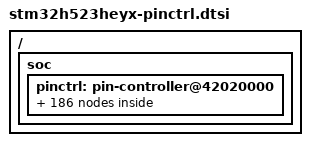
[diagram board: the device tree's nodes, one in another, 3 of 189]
/*
 * NOTE: Autogenerated file using genpinctrl.py
 *
 * SPDX-License-Identifier: Apache-2.0
 */

#include <zephyr/dt-bindings/pinctrl/stm32-pinctrl.h>

/ {
	soc {
		pinctrl: pin-controller@42020000 {

			/* ADC_IN / ADC_INN / ADC_INP */

			/omit-if-no-ref/ adc1_inn1_pa0: adc1_inn1_pa0 {
				pinmux = <STM32_PINMUX('A', 0, ANALOG)>;
			};

			/omit-if-no-ref/ adc1_inp0_pa0: adc1_inp0_pa0 {
				pinmux = <STM32_PINMUX('A', 0, ANALOG)>;
			};

			/omit-if-no-ref/ adc1_inp1_pa1: adc1_inp1_pa1 {
				pinmux = <STM32_PINMUX('A', 1, ANALOG)>;
			};

			/omit-if-no-ref/ adc1_inp14_pa2: adc1_inp14_pa2 {
				pinmux = <STM32_PINMUX('A', 2, ANALOG)>;
			};

			/omit-if-no-ref/ adc1_inp15_pa3: adc1_inp15_pa3 {
				pinmux = <STM32_PINMUX('A', 3, ANALOG)>;
			};

			/omit-if-no-ref/ adc1_inp18_pa4: adc1_inp18_pa4 {
				pinmux = <STM32_PINMUX('A', 4, ANALOG)>;
			};

			/omit-if-no-ref/ adc1_inn18_pa5: adc1_inn18_pa5 {
				pinmux = <STM32_PINMUX('A', 5, ANALOG)>;
			};

			/omit-if-no-ref/ adc1_inp19_pa5: adc1_inp19_pa5 {
				pinmux = <STM32_PINMUX('A', 5, ANALOG)>;
			};

			/omit-if-no-ref/ adc1_inp3_pa6: adc1_inp3_pa6 {
				pinmux = <STM32_PINMUX('A', 6, ANALOG)>;
			};

			/omit-if-no-ref/ adc1_inn3_pa7: adc1_inn3_pa7 {
				pinmux = <STM32_PINMUX('A', 7, ANALOG)>;
			};

			/omit-if-no-ref/ adc1_inp7_pa7: adc1_inp7_pa7 {
				pinmux = <STM32_PINMUX('A', 7, ANALOG)>;
			};

			/omit-if-no-ref/ adc1_inn5_pb0: adc1_inn5_pb0 {
				pinmux = <STM32_PINMUX('B', 0, ANALOG)>;
			};

			/omit-if-no-ref/ adc1_inp9_pb0: adc1_inp9_pb0 {
				pinmux = <STM32_PINMUX('B', 0, ANALOG)>;
			};

			/omit-if-no-ref/ adc1_inp5_pb1: adc1_inp5_pb1 {
				pinmux = <STM32_PINMUX('B', 1, ANALOG)>;
			};

			/omit-if-no-ref/ adc2_inn1_pa0: adc2_inn1_pa0 {
				pinmux = <STM32_PINMUX('A', 0, ANALOG)>;
			};

			/omit-if-no-ref/ adc2_inp0_pa0: adc2_inp0_pa0 {
				pinmux = <STM32_PINMUX('A', 0, ANALOG)>;
			};

			/omit-if-no-ref/ adc2_inp1_pa1: adc2_inp1_pa1 {
				pinmux = <STM32_PINMUX('A', 1, ANALOG)>;
			};

			/omit-if-no-ref/ adc2_inp14_pa2: adc2_inp14_pa2 {
				pinmux = <STM32_PINMUX('A', 2, ANALOG)>;
			};

			/omit-if-no-ref/ adc2_inp15_pa3: adc2_inp15_pa3 {
				pinmux = <STM32_PINMUX('A', 3, ANALOG)>;
			};

			/omit-if-no-ref/ adc2_inp18_pa4: adc2_inp18_pa4 {
				pinmux = <STM32_PINMUX('A', 4, ANALOG)>;
			};

			/omit-if-no-ref/ adc2_inn18_pa5: adc2_inn18_pa5 {
				pinmux = <STM32_PINMUX('A', 5, ANALOG)>;
			};

			/omit-if-no-ref/ adc2_inp19_pa5: adc2_inp19_pa5 {
				pinmux = <STM32_PINMUX('A', 5, ANALOG)>;
			};

			/omit-if-no-ref/ adc2_inp3_pa6: adc2_inp3_pa6 {
				pinmux = <STM32_PINMUX('A', 6, ANALOG)>;
			};

			/omit-if-no-ref/ adc2_inn3_pa7: adc2_inn3_pa7 {
				pinmux = <STM32_PINMUX('A', 7, ANALOG)>;
			};

			/omit-if-no-ref/ adc2_inp7_pa7: adc2_inp7_pa7 {
				pinmux = <STM32_PINMUX('A', 7, ANALOG)>;
			};

			/omit-if-no-ref/ adc2_inn5_pb0: adc2_inn5_pb0 {
				pinmux = <STM32_PINMUX('B', 0, ANALOG)>;
			};

			/omit-if-no-ref/ adc2_inp9_pb0: adc2_inp9_pb0 {
				pinmux = <STM32_PINMUX('B', 0, ANALOG)>;
			};

			/omit-if-no-ref/ adc2_inp5_pb1: adc2_inp5_pb1 {
				pinmux = <STM32_PINMUX('B', 1, ANALOG)>;
			};

			/* Analog */

			/omit-if-no-ref/ analog_pa0: analog_pa0 {
				pinmux = <STM32_PINMUX('A', 0, ANALOG)>;
			};

			/omit-if-no-ref/ analog_pa1: analog_pa1 {
				pinmux = <STM32_PINMUX('A', 1, ANALOG)>;
			};

			/omit-if-no-ref/ analog_pa2: analog_pa2 {
				pinmux = <STM32_PINMUX('A', 2, ANALOG)>;
			};

			/omit-if-no-ref/ analog_pa3: analog_pa3 {
				pinmux = <STM32_PINMUX('A', 3, ANALOG)>;
			};

			/omit-if-no-ref/ analog_pa4: analog_pa4 {
				pinmux = <STM32_PINMUX('A', 4, ANALOG)>;
			};

			/omit-if-no-ref/ analog_pa5: analog_pa5 {
				pinmux = <STM32_PINMUX('A', 5, ANALOG)>;
			};

			/omit-if-no-ref/ analog_pa6: analog_pa6 {
				pinmux = <STM32_PINMUX('A', 6, ANALOG)>;
			};

			/omit-if-no-ref/ analog_pa7: analog_pa7 {
				pinmux = <STM32_PINMUX('A', 7, ANALOG)>;
			};

			/omit-if-no-ref/ analog_pa8: analog_pa8 {
				pinmux = <STM32_PINMUX('A', 8, ANALOG)>;
			};

			/omit-if-no-ref/ analog_pa11: analog_pa11 {
				pinmux = <STM32_PINMUX('A', 11, ANALOG)>;
			};

			/omit-if-no-ref/ analog_pa12: analog_pa12 {
				pinmux = <STM32_PINMUX('A', 12, ANALOG)>;
			};

			/omit-if-no-ref/ analog_pa13: analog_pa13 {
				pinmux = <STM32_PINMUX('A', 13, ANALOG)>;
			};

			/omit-if-no-ref/ analog_pa14: analog_pa14 {
				pinmux = <STM32_PINMUX('A', 14, ANALOG)>;
			};

			/omit-if-no-ref/ analog_pa15: analog_pa15 {
				pinmux = <STM32_PINMUX('A', 15, ANALOG)>;
			};

			/omit-if-no-ref/ analog_pb0: analog_pb0 {
				pinmux = <STM32_PINMUX('B', 0, ANALOG)>;
			};

			/omit-if-no-ref/ analog_pb1: analog_pb1 {
				pinmux = <STM32_PINMUX('B', 1, ANALOG)>;
			};

			/omit-if-no-ref/ analog_pb3: analog_pb3 {
				pinmux = <STM32_PINMUX('B', 3, ANALOG)>;
			};

			/omit-if-no-ref/ analog_pb4: analog_pb4 {
				pinmux = <STM32_PINMUX('B', 4, ANALOG)>;
			};

			/omit-if-no-ref/ analog_pb7: analog_pb7 {
				pinmux = <STM32_PINMUX('B', 7, ANALOG)>;
			};

			/omit-if-no-ref/ analog_pb8: analog_pb8 {
				pinmux = <STM32_PINMUX('B', 8, ANALOG)>;
			};

			/omit-if-no-ref/ analog_pb15: analog_pb15 {
				pinmux = <STM32_PINMUX('B', 15, ANALOG)>;
			};

			/omit-if-no-ref/ analog_pc13: analog_pc13 {
				pinmux = <STM32_PINMUX('C', 13, ANALOG)>;
			};

			/omit-if-no-ref/ analog_pc14: analog_pc14 {
				pinmux = <STM32_PINMUX('C', 14, ANALOG)>;
			};

			/omit-if-no-ref/ analog_pc15: analog_pc15 {
				pinmux = <STM32_PINMUX('C', 15, ANALOG)>;
			};

			/omit-if-no-ref/ analog_ph0: analog_ph0 {
				pinmux = <STM32_PINMUX('H', 0, ANALOG)>;
			};

			/omit-if-no-ref/ analog_ph1: analog_ph1 {
				pinmux = <STM32_PINMUX('H', 1, ANALOG)>;
			};

			/* DAC_OUT */

			/omit-if-no-ref/ dac1_out1_pa4: dac1_out1_pa4 {
				pinmux = <STM32_PINMUX('A', 4, ANALOG)>;
			};

			/omit-if-no-ref/ dac1_out2_pa5: dac1_out2_pa5 {
				pinmux = <STM32_PINMUX('A', 5, ANALOG)>;
			};

			/* FDCAN_RX */

			/omit-if-no-ref/ fdcan1_rx_pa11: fdcan1_rx_pa11 {
				pinmux = <STM32_PINMUX('A', 11, AF9)>;
			};

			/omit-if-no-ref/ fdcan1_rx_pb8: fdcan1_rx_pb8 {
				pinmux = <STM32_PINMUX('B', 8, AF9)>;
			};

			/omit-if-no-ref/ fdcan2_rx_pa0: fdcan2_rx_pa0 {
				pinmux = <STM32_PINMUX('A', 0, AF9)>;
			};

			/* FDCAN_TX */

			/omit-if-no-ref/ fdcan1_tx_pa12: fdcan1_tx_pa12 {
				pinmux = <STM32_PINMUX('A', 12, AF9)>;
			};

			/omit-if-no-ref/ fdcan1_tx_pb7: fdcan1_tx_pb7 {
				pinmux = <STM32_PINMUX('B', 7, AF9)>;
			};

			/omit-if-no-ref/ fdcan2_tx_pb3: fdcan2_tx_pb3 {
				pinmux = <STM32_PINMUX('B', 3, AF9)>;
			};

			/* I2C_SCL */

			/omit-if-no-ref/ i2c1_scl_pb8: i2c1_scl_pb8 {
				pinmux = <STM32_PINMUX('B', 8, AF4)>;
				bias-pull-up;
				drive-open-drain;
			};

			/* I2C_SDA */

			/omit-if-no-ref/ i2c1_sda_pb7: i2c1_sda_pb7 {
				pinmux = <STM32_PINMUX('B', 7, AF4)>;
				bias-pull-up;
				drive-open-drain;
			};

			/omit-if-no-ref/ i2c2_sda_pb3: i2c2_sda_pb3 {
				pinmux = <STM32_PINMUX('B', 3, AF4)>;
				bias-pull-up;
				drive-open-drain;
			};

			/* I2S_CK */

			/omit-if-no-ref/ i2s1_ck_pa5: i2s1_ck_pa5 {
				pinmux = <STM32_PINMUX('A', 5, AF5)>;
				slew-rate = "very-high-speed";
			};

			/omit-if-no-ref/ i2s1_ck_pb3: i2s1_ck_pb3 {
				pinmux = <STM32_PINMUX('B', 3, AF5)>;
				slew-rate = "very-high-speed";
			};

			/omit-if-no-ref/ i2s2_ck_pa12: i2s2_ck_pa12 {
				pinmux = <STM32_PINMUX('A', 12, AF5)>;
				slew-rate = "very-high-speed";
			};

			/* I2S_WS */

			/omit-if-no-ref/ i2s1_ws_pa4: i2s1_ws_pa4 {
				pinmux = <STM32_PINMUX('A', 4, AF5)>;
			};

			/omit-if-no-ref/ i2s1_ws_pa15: i2s1_ws_pa15 {
				pinmux = <STM32_PINMUX('A', 15, AF5)>;
			};

			/omit-if-no-ref/ i2s2_ws_pa3: i2s2_ws_pa3 {
				pinmux = <STM32_PINMUX('A', 3, AF5)>;
			};

			/omit-if-no-ref/ i2s2_ws_pa11: i2s2_ws_pa11 {
				pinmux = <STM32_PINMUX('A', 11, AF5)>;
			};

			/omit-if-no-ref/ i2s2_ws_pb1: i2s2_ws_pb1 {
				pinmux = <STM32_PINMUX('B', 1, AF5)>;
			};

			/omit-if-no-ref/ i2s2_ws_pb4: i2s2_ws_pb4 {
				pinmux = <STM32_PINMUX('B', 4, AF7)>;
			};

			/* I3C_SCL */

			/omit-if-no-ref/ i3c1_scl_pb8: i3c1_scl_pb8 {
				pinmux = <STM32_PINMUX('B', 8, AF3)>;
				slew-rate = "very-high-speed";
			};

			/omit-if-no-ref/ i3c2_scl_pa8: i3c2_scl_pa8 {
				pinmux = <STM32_PINMUX('A', 8, AF9)>;
				slew-rate = "very-high-speed";
			};

			/omit-if-no-ref/ i3c2_scl_pb3: i3c2_scl_pb3 {
				pinmux = <STM32_PINMUX('B', 3, AF3)>;
				slew-rate = "very-high-speed";
			};

			/* I3C_SDA */

			/omit-if-no-ref/ i3c1_sda_pb7: i3c1_sda_pb7 {
				pinmux = <STM32_PINMUX('B', 7, AF3)>;
				slew-rate = "very-high-speed";
			};

			/omit-if-no-ref/ i3c2_sda_pb4: i3c2_sda_pb4 {
				pinmux = <STM32_PINMUX('B', 4, AF10)>;
				slew-rate = "very-high-speed";
			};

			/* JTAG PORT */

			/omit-if-no-ref/ debug_jtms_swdio_pa13: debug_jtms_swdio_pa13 {
				pinmux = <STM32_PINMUX('A', 13, AF0)>;
			};

			/omit-if-no-ref/ debug_jtck_swclk_pa14: debug_jtck_swclk_pa14 {
				pinmux = <STM32_PINMUX('A', 14, AF0)>;
			};

			/omit-if-no-ref/ debug_jtdi_pa15: debug_jtdi_pa15 {
				pinmux = <STM32_PINMUX('A', 15, AF0)>;
			};

			/omit-if-no-ref/ debug_jtdo_swo_pb3: debug_jtdo_swo_pb3 {
				pinmux = <STM32_PINMUX('B', 3, AF0)>;
			};

			/omit-if-no-ref/ debug_njtrst_pb4: debug_njtrst_pb4 {
				pinmux = <STM32_PINMUX('B', 4, AF0)>;
			};

			/* OCTOSPI */

			/omit-if-no-ref/ octospi1_dqs_pa1: octospi1_dqs_pa1 {
				pinmux = <STM32_PINMUX('A', 1, AF6)>;
				slew-rate = "very-high-speed";
			};

			/omit-if-no-ref/ octospi1_io3_pa1: octospi1_io3_pa1 {
				pinmux = <STM32_PINMUX('A', 1, AF9)>;
				slew-rate = "very-high-speed";
			};

			/omit-if-no-ref/ octospi1_clk_pa3: octospi1_clk_pa3 {
				pinmux = <STM32_PINMUX('A', 3, AF3)>;
				slew-rate = "very-high-speed";
			};

			/omit-if-no-ref/ octospi1_io3_pa6: octospi1_io3_pa6 {
				pinmux = <STM32_PINMUX('A', 6, AF6)>;
				slew-rate = "very-high-speed";
			};

			/omit-if-no-ref/ octospi1_io2_pa7: octospi1_io2_pa7 {
				pinmux = <STM32_PINMUX('A', 7, AF10)>;
				slew-rate = "very-high-speed";
			};

			/omit-if-no-ref/ octospi1_ncs_pa15: octospi1_ncs_pa15 {
				pinmux = <STM32_PINMUX('A', 15, AF9)>;
				slew-rate = "very-high-speed";
			};

			/omit-if-no-ref/ octospi1_io1_pb0: octospi1_io1_pb0 {
				pinmux = <STM32_PINMUX('B', 0, AF6)>;
				slew-rate = "very-high-speed";
			};

			/omit-if-no-ref/ octospi1_io0_pb1: octospi1_io0_pb1 {
				pinmux = <STM32_PINMUX('B', 1, AF6)>;
				slew-rate = "very-high-speed";
			};

			/omit-if-no-ref/ octospi1_clk_pb4: octospi1_clk_pb4 {
				pinmux = <STM32_PINMUX('B', 4, AF3)>;
				slew-rate = "very-high-speed";
			};

			/omit-if-no-ref/ octospi1_clk_pb15: octospi1_clk_pb15 {
				pinmux = <STM32_PINMUX('B', 15, AF10)>;
				slew-rate = "very-high-speed";
			};

			/* RCC_MCO */

			/omit-if-no-ref/ rcc_mco_1_pa8: rcc_mco_1_pa8 {
				pinmux = <STM32_PINMUX('A', 8, AF0)>;
				slew-rate = "very-high-speed";
			};

			/* SPI_MISO */

			/omit-if-no-ref/ spi1_miso_pa6: spi1_miso_pa6 {
				pinmux = <STM32_PINMUX('A', 6, AF5)>;
				bias-pull-down;
			};

			/omit-if-no-ref/ spi1_miso_pb4: spi1_miso_pb4 {
				pinmux = <STM32_PINMUX('B', 4, AF5)>;
				bias-pull-down;
			};

			/omit-if-no-ref/ spi3_miso_pb0: spi3_miso_pb0 {
				pinmux = <STM32_PINMUX('B', 0, AF5)>;
				bias-pull-down;
			};

			/omit-if-no-ref/ spi3_miso_pb4: spi3_miso_pb4 {
				pinmux = <STM32_PINMUX('B', 4, AF6)>;
				bias-pull-down;
			};

			/* SPI_MOSI */

			/omit-if-no-ref/ spi1_mosi_pa7: spi1_mosi_pa7 {
				pinmux = <STM32_PINMUX('A', 7, AF5)>;
				bias-pull-down;
			};

			/omit-if-no-ref/ spi1_mosi_pb15: spi1_mosi_pb15 {
				pinmux = <STM32_PINMUX('B', 15, AF6)>;
				bias-pull-down;
			};

			/omit-if-no-ref/ spi2_mosi_pb15: spi2_mosi_pb15 {
				pinmux = <STM32_PINMUX('B', 15, AF5)>;
				bias-pull-down;
			};

			/omit-if-no-ref/ spi3_mosi_pa3: spi3_mosi_pa3 {
				pinmux = <STM32_PINMUX('A', 3, AF6)>;
				bias-pull-down;
			};

			/omit-if-no-ref/ spi3_mosi_pa4: spi3_mosi_pa4 {
				pinmux = <STM32_PINMUX('A', 4, AF4)>;
				bias-pull-down;
			};

			/* SPI_NSS */

			/omit-if-no-ref/ spi1_nss_pa4: spi1_nss_pa4 {
				pinmux = <STM32_PINMUX('A', 4, AF5)>;
				bias-pull-up;
			};

			/omit-if-no-ref/ spi1_nss_pa15: spi1_nss_pa15 {
				pinmux = <STM32_PINMUX('A', 15, AF5)>;
				bias-pull-up;
			};

			/omit-if-no-ref/ spi2_nss_pa3: spi2_nss_pa3 {
				pinmux = <STM32_PINMUX('A', 3, AF5)>;
				bias-pull-up;
			};

			/omit-if-no-ref/ spi2_nss_pa11: spi2_nss_pa11 {
				pinmux = <STM32_PINMUX('A', 11, AF5)>;
				bias-pull-up;
			};

			/omit-if-no-ref/ spi2_nss_pb1: spi2_nss_pb1 {
				pinmux = <STM32_PINMUX('B', 1, AF5)>;
				bias-pull-up;
			};

			/omit-if-no-ref/ spi2_nss_pb4: spi2_nss_pb4 {
				pinmux = <STM32_PINMUX('B', 4, AF7)>;
				bias-pull-up;
			};

			/omit-if-no-ref/ spi3_nss_pa4: spi3_nss_pa4 {
				pinmux = <STM32_PINMUX('A', 4, AF6)>;
				bias-pull-up;
			};

			/omit-if-no-ref/ spi3_nss_pa15: spi3_nss_pa15 {
				pinmux = <STM32_PINMUX('A', 15, AF6)>;
				bias-pull-up;
			};

			/omit-if-no-ref/ spi3_nss_pb8: spi3_nss_pb8 {
				pinmux = <STM32_PINMUX('B', 8, AF6)>;
				bias-pull-up;
			};

			/* SPI_SCK */

			/omit-if-no-ref/ spi1_sck_pa5: spi1_sck_pa5 {
				pinmux = <STM32_PINMUX('A', 5, AF5)>;
				bias-pull-down;
				slew-rate = "very-high-speed";
			};

			/omit-if-no-ref/ spi1_sck_pb3: spi1_sck_pb3 {
				pinmux = <STM32_PINMUX('B', 3, AF5)>;
				bias-pull-down;
				slew-rate = "very-high-speed";
			};

			/omit-if-no-ref/ spi2_sck_pa12: spi2_sck_pa12 {
				pinmux = <STM32_PINMUX('A', 12, AF5)>;
				bias-pull-down;
				slew-rate = "very-high-speed";
			};

			/omit-if-no-ref/ spi3_sck_pb1: spi3_sck_pb1 {
				pinmux = <STM32_PINMUX('B', 1, AF4)>;
				bias-pull-down;
				slew-rate = "very-high-speed";
			};

			/omit-if-no-ref/ spi3_sck_pb3: spi3_sck_pb3 {
				pinmux = <STM32_PINMUX('B', 3, AF6)>;
				bias-pull-down;
				slew-rate = "very-high-speed";
			};

			/* TIM_BKIN */

			/omit-if-no-ref/ tim1_bkin_pa6: tim1_bkin_pa6 {
				pinmux = <STM32_PINMUX('A', 6, AF1)>;
			};

			/omit-if-no-ref/ tim15_bkin_pa0: tim15_bkin_pa0 {
				pinmux = <STM32_PINMUX('A', 0, AF4)>;
			};

			/omit-if-no-ref/ tim8_bkin_pa6: tim8_bkin_pa6 {
				pinmux = <STM32_PINMUX('A', 6, AF3)>;
			};

			/omit-if-no-ref/ tim8_bkin2_pa8: tim8_bkin2_pa8 {
				pinmux = <STM32_PINMUX('A', 8, AF3)>;
			};

			/* TIM_CH / TIM_CHN */

			/omit-if-no-ref/ tim1_ch1n_pa7: tim1_ch1n_pa7 {
				pinmux = <STM32_PINMUX('A', 7, AF1)>;
			};

			/omit-if-no-ref/ tim1_ch1_pa8: tim1_ch1_pa8 {
				pinmux = <STM32_PINMUX('A', 8, AF1)>;
			};

			/omit-if-no-ref/ tim1_ch4_pa11: tim1_ch4_pa11 {
				pinmux = <STM32_PINMUX('A', 11, AF1)>;
			};

			/omit-if-no-ref/ tim1_ch2n_pb0: tim1_ch2n_pb0 {
				pinmux = <STM32_PINMUX('B', 0, AF1)>;
			};

			/omit-if-no-ref/ tim1_ch3n_pb1: tim1_ch3n_pb1 {
				pinmux = <STM32_PINMUX('B', 1, AF1)>;
			};

			/omit-if-no-ref/ tim1_ch3n_pb15: tim1_ch3n_pb15 {
				pinmux = <STM32_PINMUX('B', 15, AF1)>;
			};

			/omit-if-no-ref/ tim2_ch1_pa0: tim2_ch1_pa0 {
				pinmux = <STM32_PINMUX('A', 0, AF1)>;
			};

			/omit-if-no-ref/ tim2_ch2_pa1: tim2_ch2_pa1 {
				pinmux = <STM32_PINMUX('A', 1, AF1)>;
			};

			/omit-if-no-ref/ tim2_ch3_pa2: tim2_ch3_pa2 {
				pinmux = <STM32_PINMUX('A', 2, AF1)>;
			};

			/omit-if-no-ref/ tim2_ch4_pa3: tim2_ch4_pa3 {
				pinmux = <STM32_PINMUX('A', 3, AF1)>;
			};

			/omit-if-no-ref/ tim2_ch1_pa5: tim2_ch1_pa5 {
				pinmux = <STM32_PINMUX('A', 5, AF1)>;
			};

			/omit-if-no-ref/ tim2_ch1_pa15: tim2_ch1_pa15 {
				pinmux = <STM32_PINMUX('A', 15, AF1)>;
			};

			/omit-if-no-ref/ tim2_ch2_pb3: tim2_ch2_pb3 {
				pinmux = <STM32_PINMUX('B', 3, AF1)>;
			};

			/omit-if-no-ref/ tim12_ch2_pb15: tim12_ch2_pb15 {
				pinmux = <STM32_PINMUX('B', 15, AF2)>;
			};

			/omit-if-no-ref/ tim3_ch1_pa6: tim3_ch1_pa6 {
				pinmux = <STM32_PINMUX('A', 6, AF2)>;
			};

			/omit-if-no-ref/ tim3_ch2_pa7: tim3_ch2_pa7 {
				pinmux = <STM32_PINMUX('A', 7, AF2)>;
			};

			/omit-if-no-ref/ tim3_ch3_pb0: tim3_ch3_pb0 {
				pinmux = <STM32_PINMUX('B', 0, AF2)>;
			};

			/omit-if-no-ref/ tim3_ch4_pb1: tim3_ch4_pb1 {
				pinmux = <STM32_PINMUX('B', 1, AF2)>;
			};

			/omit-if-no-ref/ tim3_ch1_pb4: tim3_ch1_pb4 {
				pinmux = <STM32_PINMUX('B', 4, AF2)>;
			};

			/omit-if-no-ref/ tim4_ch2_pb7: tim4_ch2_pb7 {
				pinmux = <STM32_PINMUX('B', 7, AF2)>;
			};

			/omit-if-no-ref/ tim4_ch3_pb8: tim4_ch3_pb8 {
				pinmux = <STM32_PINMUX('B', 8, AF2)>;
			};

			/omit-if-no-ref/ tim5_ch1_pa0: tim5_ch1_pa0 {
				pinmux = <STM32_PINMUX('A', 0, AF2)>;
			};

			/omit-if-no-ref/ tim15_ch1n_pa1: tim15_ch1n_pa1 {
				pinmux = <STM32_PINMUX('A', 1, AF4)>;
			};

			/omit-if-no-ref/ tim5_ch2_pa1: tim5_ch2_pa1 {
				pinmux = <STM32_PINMUX('A', 1, AF2)>;
			};

			/omit-if-no-ref/ tim15_ch1_pa2: tim15_ch1_pa2 {
				pinmux = <STM32_PINMUX('A', 2, AF4)>;
			};

			/omit-if-no-ref/ tim5_ch3_pa2: tim5_ch3_pa2 {
				pinmux = <STM32_PINMUX('A', 2, AF2)>;
			};

			/omit-if-no-ref/ tim15_ch2_pa3: tim15_ch2_pa3 {
				pinmux = <STM32_PINMUX('A', 3, AF4)>;
			};

			/omit-if-no-ref/ tim5_ch4_pa3: tim5_ch4_pa3 {
				pinmux = <STM32_PINMUX('A', 3, AF2)>;
			};

			/omit-if-no-ref/ tim8_ch1n_pa5: tim8_ch1n_pa5 {
				pinmux = <STM32_PINMUX('A', 5, AF3)>;
			};

			/omit-if-no-ref/ tim8_ch1n_pa7: tim8_ch1n_pa7 {
				pinmux = <STM32_PINMUX('A', 7, AF3)>;
			};

			/omit-if-no-ref/ tim8_ch2n_pb0: tim8_ch2n_pb0 {
				pinmux = <STM32_PINMUX('B', 0, AF3)>;
			};

			/omit-if-no-ref/ tim8_ch3n_pb1: tim8_ch3n_pb1 {
				pinmux = <STM32_PINMUX('B', 1, AF3)>;
			};

			/omit-if-no-ref/ tim8_ch3n_pb15: tim8_ch3n_pb15 {
				pinmux = <STM32_PINMUX('B', 15, AF3)>;
			};

			/* UART_CTS / USART_CTS / LPUART_CTS */

			/omit-if-no-ref/ lpuart1_cts_pa11: lpuart1_cts_pa11 {
				pinmux = <STM32_PINMUX('A', 11, AF3)>;
				bias-pull-up;
			};

			/omit-if-no-ref/ usart1_cts_pa11: usart1_cts_pa11 {
				pinmux = <STM32_PINMUX('A', 11, AF7)>;
				bias-pull-up;
			};

			/omit-if-no-ref/ usart2_cts_pa0: usart2_cts_pa0 {
				pinmux = <STM32_PINMUX('A', 0, AF7)>;
				bias-pull-up;
			};

			/omit-if-no-ref/ uart4_cts_pb0: uart4_cts_pb0 {
				pinmux = <STM32_PINMUX('B', 0, AF8)>;
				bias-pull-up;
			};

			/omit-if-no-ref/ uart4_cts_pb15: uart4_cts_pb15 {
				pinmux = <STM32_PINMUX('B', 15, AF8)>;
				bias-pull-up;
			};

			/* UART_DE / USART_DE / LPUART_DE */

			/omit-if-no-ref/ lpuart1_de_pa12: lpuart1_de_pa12 {
				pinmux = <STM32_PINMUX('A', 12, AF3)>;
				drive-push-pull;
			};

			/omit-if-no-ref/ usart1_de_pa12: usart1_de_pa12 {
				pinmux = <STM32_PINMUX('A', 12, AF7)>;
				drive-push-pull;
			};

			/omit-if-no-ref/ usart2_de_pa1: usart2_de_pa1 {
				pinmux = <STM32_PINMUX('A', 1, AF7)>;
				drive-push-pull;
			};

			/omit-if-no-ref/ uart4_de_pa15: uart4_de_pa15 {
				pinmux = <STM32_PINMUX('A', 15, AF8)>;
				drive-push-pull;
			};

			/* UART_RTS / USART_RTS / LPUART_RTS */

			/omit-if-no-ref/ lpuart1_rts_pa12: lpuart1_rts_pa12 {
				pinmux = <STM32_PINMUX('A', 12, AF3)>;
				drive-push-pull;
			};

			/omit-if-no-ref/ usart1_rts_pa12: usart1_rts_pa12 {
				pinmux = <STM32_PINMUX('A', 12, AF7)>;
				drive-push-pull;
			};

			/omit-if-no-ref/ usart2_rts_pa1: usart2_rts_pa1 {
				pinmux = <STM32_PINMUX('A', 1, AF7)>;
				drive-push-pull;
			};

			/omit-if-no-ref/ uart4_rts_pa15: uart4_rts_pa15 {
				pinmux = <STM32_PINMUX('A', 15, AF8)>;
				drive-push-pull;
			};

			/* UART_RX / USART_RX / LPUART_RX */

			/omit-if-no-ref/ lpuart1_rx_pb7: lpuart1_rx_pb7 {
				pinmux = <STM32_PINMUX('B', 7, AF8)>;
			};

			/omit-if-no-ref/ usart1_rx_pb7: usart1_rx_pb7 {
				pinmux = <STM32_PINMUX('B', 7, AF7)>;
			};

			/omit-if-no-ref/ usart1_rx_pb15: usart1_rx_pb15 {
				pinmux = <STM32_PINMUX('B', 15, AF4)>;
			};

			/omit-if-no-ref/ usart2_rx_pa3: usart2_rx_pa3 {
				pinmux = <STM32_PINMUX('A', 3, AF7)>;
			};

			/omit-if-no-ref/ uart4_rx_pa1: uart4_rx_pa1 {
				pinmux = <STM32_PINMUX('A', 1, AF8)>;
			};

			/omit-if-no-ref/ uart4_rx_pa11: uart4_rx_pa11 {
				pinmux = <STM32_PINMUX('A', 11, AF6)>;
			};

			/omit-if-no-ref/ uart4_rx_pb8: uart4_rx_pb8 {
				pinmux = <STM32_PINMUX('B', 8, AF8)>;
			};

			/omit-if-no-ref/ uart5_rx_pb15: uart5_rx_pb15 {
				pinmux = <STM32_PINMUX('B', 15, AF14)>;
			};

			/* UART_TX / USART_TX / LPUART_TX */

			/omit-if-no-ref/ lpuart1_tx_pa2: lpuart1_tx_pa2 {
				pinmux = <STM32_PINMUX('A', 2, AF3)>;
				bias-pull-up;
			};

			/omit-if-no-ref/ usart1_tx_pa15: usart1_tx_pa15 {
				pinmux = <STM32_PINMUX('A', 15, AF7)>;
				bias-pull-up;
			};

			/omit-if-no-ref/ lpuart1_tx_pb3: lpuart1_tx_pb3 {
				pinmux = <STM32_PINMUX('B', 3, AF8)>;
				bias-pull-up;
			};

			/omit-if-no-ref/ usart2_tx_pa2: usart2_tx_pa2 {
				pinmux = <STM32_PINMUX('A', 2, AF7)>;
				bias-pull-up;
			};

			/omit-if-no-ref/ usart2_tx_pb0: usart2_tx_pb0 {
				pinmux = <STM32_PINMUX('B', 0, AF7)>;
				bias-pull-up;
			};

			/omit-if-no-ref/ uart4_tx_pa0: uart4_tx_pa0 {
				pinmux = <STM32_PINMUX('A', 0, AF8)>;
				bias-pull-up;
			};

			/omit-if-no-ref/ uart4_tx_pa12: uart4_tx_pa12 {
				pinmux = <STM32_PINMUX('A', 12, AF6)>;
				bias-pull-up;
			};

			/omit-if-no-ref/ uart5_tx_pb3: uart5_tx_pb3 {
				pinmux = <STM32_PINMUX('B', 3, AF14)>;
				bias-pull-up;
			};

			/* USB */

			/omit-if-no-ref/ usb_dm_pa11: usb_dm_pa11 {
				pinmux = <STM32_PINMUX('A', 11, AF10)>;
			};

			/omit-if-no-ref/ usb_dp_pa12: usb_dp_pa12 {
				pinmux = <STM32_PINMUX('A', 12, AF10)>;
			};

		};
	};
};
